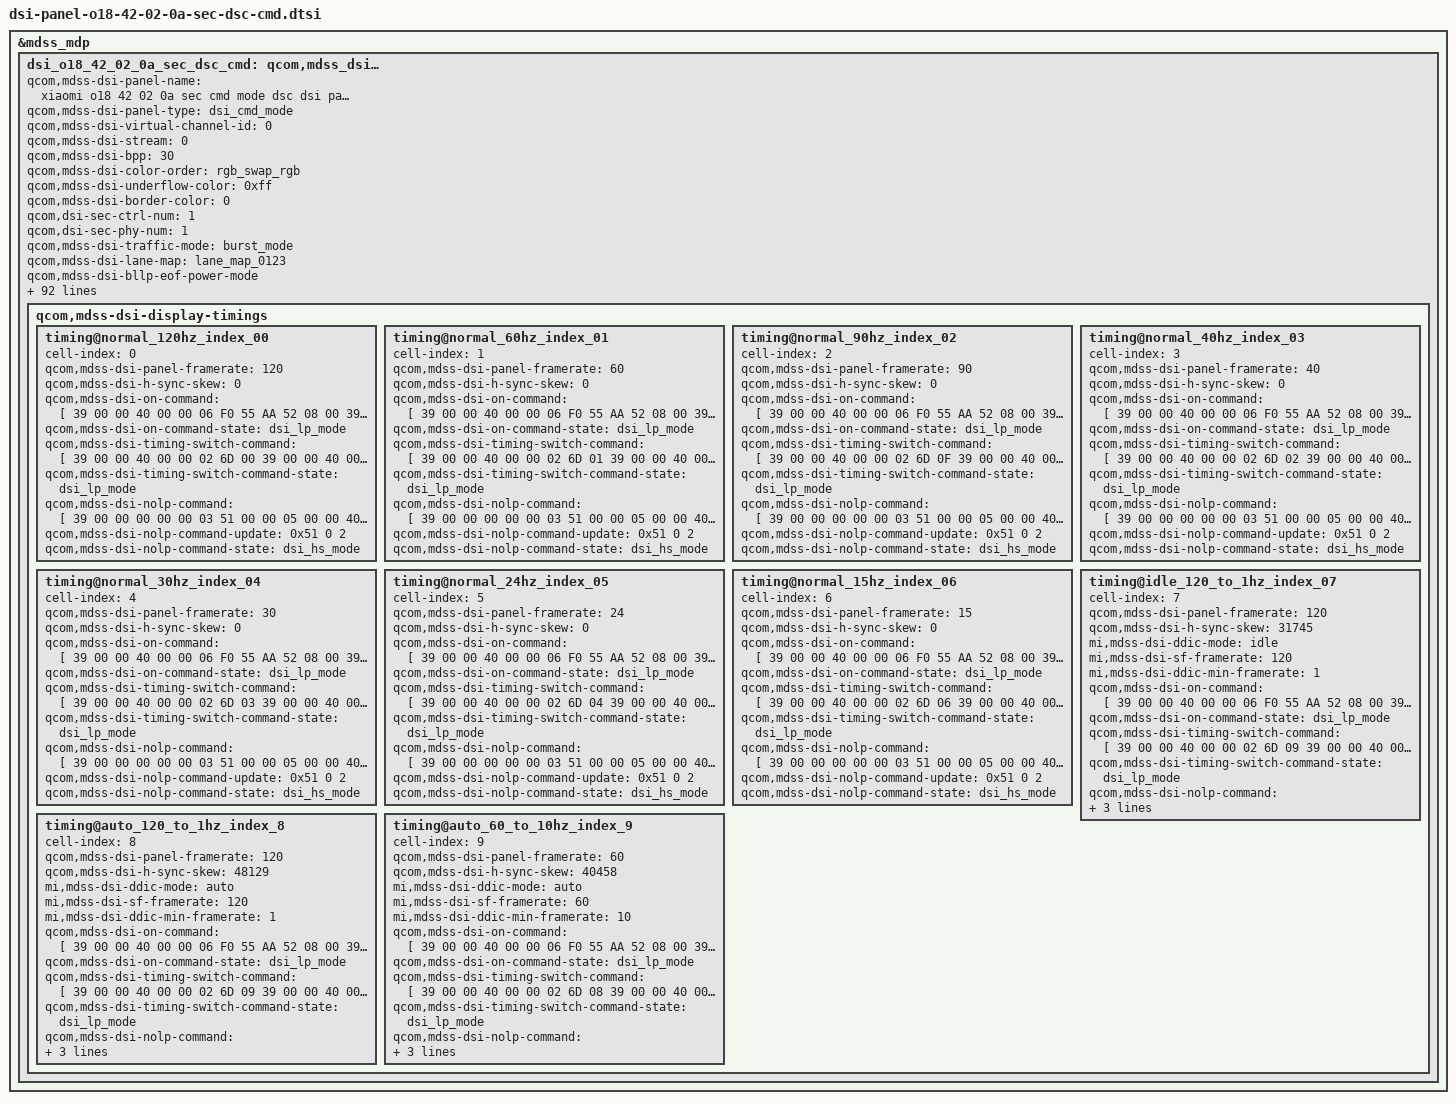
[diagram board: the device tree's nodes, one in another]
&mdss_mdp {
	dsi_o18_42_02_0a_sec_dsc_cmd: qcom,mdss_dsi_o18_42_02_0a_sec_dsc_cmd {
		qcom,mdss-dsi-panel-name = "xiaomi o18 42 02 0a sec cmd mode dsc dsi panel";
		qcom,mdss-dsi-panel-type = "dsi_cmd_mode";
		qcom,mdss-dsi-virtual-channel-id = <0>;
		qcom,mdss-dsi-stream = <0>;
		qcom,mdss-dsi-bpp = <30>;
		qcom,mdss-dsi-color-order = "rgb_swap_rgb";
		qcom,mdss-dsi-underflow-color = <0xff>;
		qcom,mdss-dsi-border-color = <0>;
		qcom,dsi-sec-ctrl-num = <1>;
		qcom,dsi-sec-phy-num = <1>;

		qcom,mdss-dsi-traffic-mode = "burst_mode";
		qcom,mdss-dsi-lane-map = "lane_map_0123";
		qcom,mdss-dsi-bllp-eof-power-mode;
		qcom,mdss-dsi-bllp-power-mode;
		qcom,mdss-dsi-lane-0-state;
		qcom,mdss-dsi-lane-1-state;
		qcom,mdss-dsi-lane-2-state;
		qcom,mdss-dsi-lane-3-state;
		qcom,mdss-dsi-dma-trigger = "trigger_sw";
		qcom,mdss-dsi-mdp-trigger = "none";
		qcom,mdss-dsi-reset-sequence = <0 1>, <1 10>;
		qcom,mdss-pan-physical-width-dimension = <656>;
		qcom,mdss-pan-physical-height-dimension = <1533>;
		qcom,mdss-dsi-te-pin-select = <1>;
		qcom,mdss-dsi-wr-mem-start = <0x2c>;
		qcom,mdss-dsi-wr-mem-continue = <0x3c>;
		qcom,mdss-dsi-te-dcs-command = <1>;
		qcom,mdss-dsi-te-check-enable;
		qcom,mdss-dsi-te-using-te-pin;
		qcom,mdss-dsi-tx-eot-append;
		qcom,mdss-dsi-lp11-init;

		qcom,mdss-dsi-bl-inverted-dbv;
		qcom,bl-update-flag = "delay_until_first_frame";

		qcom,mdss-dsi-panel-hdr-enabled;
		qcom,mdss-dsi-panel-hdr-color-primaries = <14500 15500 32000
			17000 15500 30000 8000 3000>;
		qcom,mdss-dsi-panel-peak-brightness = <17000000>;
		qcom,mdss-dsi-panel-blackness-level = <3230>;

		qcom,mdss-dsi-dma-schedule-line = <1>;
		qcom,mdss-dsi-dma-schedule-window = <50>;

		/* IRQF_ONESHOT | IRQF_TRIGGER_HIGH */
		/*mi,esd-err-irq-gpio = <&tlmm 137 0x2004>;*/
		//qcom,spr-pack-type = "pentile";

		mi,panel-id = <0x004F3138 0x5342020A>;

		mi,ddic-round-corner-enabled;
		qcom,mdss-disable-cesta-hw-sleep;

		mi,flat-need-sync-te;
		mi,flatmode-default-on-enabled;

		mi,flatmode-status-check-enabled;
		mi,mdss-dsi-panel-flatmode-status-command = [
			06 01 00 01 00 00 01 5F
		];
		mi,mdss-dsi-panel-flatmode-status-command-state = "dsi_hs_mode";
		mi,mdss-dsi-panel-flatmode-status-read-length = <2>;
		mi,mdss-dsi-panel-flatmode-on-status-value = <0x00>,<0x40>;

		mi,mdss-dsi-panel-wp-read-command = [06 01 00 01 00 00 01 DF];
		mi,mdss-dsi-panel-wp-read-command-state = "dsi_hs_mode";
		mi,mdss-dsi-panel-wp-read-pre-tx-command = [39 00 00 40 00 00 06 F0 55 AA 52 08 03];
		mi,mdss-dsi-panel-wp-read-pre-tx-command-state = "dsi_hs_mode";
		mi,mdss-dsi-panel-wp-read-length = <16>;

		mi,mdss-dsi-panel-cell-id-read-command = [06 01 00 01 00 00 01 B1];
		mi,mdss-dsi-panel-cell-id-read-pre-tx-command = [
			39 00 00 40 00 00 06 F0 55 AA 52 08 00
			15 00 00 00 00 00 02 EA 10
		];
		mi,mdss-dsi-panel-cell-id-read-after-tx-command = [
			39 00 00 40 00 00 06 F0 55 AA 52 08 00
			15 00 00 00 00 00 02 EA 00
		];
		mi,mdss-dsi-panel-cell-id-read-pre-tx-command-state = "dsi_hs_mode";
		mi,mdss-dsi-panel-cell-id-read-after-tx-command-state = "dsi_hs_mode";
		mi,mdss-dsi-panel-cell-id-read-command-state = "dsi_hs_mode";
		mi,mdss-dsi-panel-cell-id-read-length = <13>;
		/* esd-check reg_read */
		//qcom,esd-check-enabled;
		//qcom,esd-aod-check-enabled;
		//mi,mdss-dsi-panel-status-check-interval = <1000>;
		//qcom,mdss-dsi-panel-status-check-mode = "reg_read";
		//mi,mdss-dsi-panel-status-offset-command = [39 00 00 00 00 00 03 FF 5A 82
		//						  39 00 00 00 00 00 02 65 01];
		//qcom,mdss-dsi-panel-status-command = [06 01 00 00 00 00 01 F9];
		//mi,mdss-dsi-panel-status-after-command = [39 00 00 00 00 00 03 FF 5A 00];
		//qcom,mdss-dsi-panel-status-command-state = "dsi_lp_mode";
		//mi,mdss-dsi-panel-status-offset-command-state = "dsi_lp_mode";
		//mi,mdss-dsi-panel-status-after-command-state = "dsi_lp_mode";
		//qcom,mdss-dsi-panel-status-value = <0x08>;
		//qcom,mdss-dsi-panel-status-read-length = <1>;

		mi,panel-on-dimming-delay = <120>;
		mi,max-brightness-clone = <16383>;

		mi,mdss-dsi-fac-bl-max-level = <11467>;
		mi,mdss-fac-brightness-max-level = <11467>;
		mi,doze-hbm-dbv-level = <984>;
		mi,doze-lbm-dbv-level = <65>;

		qcom,mdss-dsi-display-timings {
			timing@normal_120hz_index_00 {
				#include "dsi-panel-o18-42-02-0a-sec-dsc-cmd-common.dtsi"
				cell-index = <0>;
				qcom,mdss-dsi-panel-framerate = <120>;
				qcom,mdss-dsi-h-sync-skew = <0>;
				qcom,mdss-dsi-on-command = [
					39 00 00 40 00 00 06 F0 55 AA 52 08 00
					39 00 00 40 00 00 02 6F 78
					39 00 00 40 00 00 18 B0 11 00 2A 00 C2 01 DA 03 7C 05 B1 08 80 0B EE 0F FF 05 55 05 56 05 55
					39 00 00 40 00 00 02 6F 6F
					39 00 00 40 00 00 07 B0 02 1C 04 38 02 1C
					39 00 00 40 00 00 06 F0 55 AA 52 08 08
					39 00 00 40 00 00 17 C1 8D FF DD FF FF DD FF FF DD FF FF EE FF FF EE FF FF FE FF FF 0D FF
					39 00 00 40 00 00 02 6F 20
					39 00 00 40 00 00 04 C1 4F 00 FF
					39 00 00 40 00 00 02 6F 23
					39 00 00 40 00 00 15 C1 0D FF DD FF FF DD FF FF DD FF FF EE FF FF EE FF FF CE FF 51
					39 00 00 40 00 00 06 F0 55 AA 52 08 00
					39 00 00 40 00 00 02 C7 33
					39 00 00 40 00 00 02 6F 31
					39 00 00 40 00 00 03 C0 02 00
					39 00 00 40 00 00 06 F0 55 AA 52 08 04
					39 00 00 40 00 00 02 C0 20
					39 00 00 40 00 00 06 F0 55 AA 52 08 01
					39 00 00 40 00 00 03 B0 17 17
					39 00 00 40 00 00 06 B2 00 00 FF 03 20
					39 00 00 40 00 00 05 FF AA 55 A5 80
					39 00 00 40 00 00 02 6F 0A
					39 00 00 40 00 00 06 F6 70 70 70 70 70
					39 00 00 40 00 00 05 FF AA 55 A5 81
					39 00 00 40 00 00 02 6F 0C
					39 00 00 40 00 00 02 FD 08
					39 00 00 40 00 00 05 FF AA 55 A5 81
					39 00 00 40 00 00 02 6F 10
					39 00 00 40 00 00 02 FB 40
					39 00 00 40 00 00 05 FF AA 55 A5 81
					39 00 00 40 00 00 02 6F 13
					39 00 00 40 00 00 02 F9 00
					39 00 00 40 00 00 02 17 30
					39 00 00 40 00 00 05 2A 00 00 04 37
					39 00 00 40 00 00 05 2B 00 00 09 D7
					39 00 00 40 00 00 02 90 03
					39 00 00 40 00 00 02 6F 01
					39 00 00 40 00 00 02 90 43
					39 00 00 40 00 00 13 91 AB A8 00 14 C2 00 02 0E 01 E8 00 07 05 0E 05 16 10 F0
					39 00 00 40 00 00 02 6F 06
					39 00 00 40 00 00 02 6D 04
					39 00 00 40 00 00 02 2F 00
					39 00 00 40 00 00 03 5F 00 40
					39 00 00 40 00 00 02 35 00
					39 00 00 40 00 00 02 53 20
					39 00 00 40 00 00 02 26 00
					39 00 00 40 00 00 02 5A 00
					39 00 00 40 00 00 02 2F 30
					/* normal 120hz */
					39 00 00 40 00 00 02 6D 00
					39 00 00 40 00 00 02 6F 04
					39 00 00 40 00 00 02 35 00
					39 00 00 40 00 00 06 F0 55 AA 52 08 00
					39 00 00 40 00 00 02 6F DE
					39 00 00 40 00 00 02 BA 04
					39 00 00 00 00 00 04 8C 02 00 11
					05 00 00 00 78 00 01 11
					05 00 00 00 00 00 01 29
				];
				qcom,mdss-dsi-on-command-state = "dsi_lp_mode";

				qcom,mdss-dsi-timing-switch-command = [
					39 00 00 40 00 00 02 6D 00
					39 00 00 40 00 00 02 6F 04
					39 00 00 40 00 00 02 35 00
					39 00 00 40 00 00 06 F0 55 AA 52 08 00
					39 00 00 40 00 00 02 6F DE
					39 00 00 40 00 00 02 BA 04
					39 00 00 00 00 00 04 8C 02 00 11
				];
				qcom,mdss-dsi-timing-switch-command-state = "dsi_lp_mode";

				qcom,mdss-dsi-nolp-command = [
					39 00 00 00 00 00 03 51 00 00
					/* AOD OFF */
					05 00 00 40 00 00 01 38
				];
				qcom,mdss-dsi-nolp-command-update = <0x51 0 2>;
				qcom,mdss-dsi-nolp-command-state = "dsi_hs_mode";

			};
			timing@normal_60hz_index_01 {
				#include "dsi-panel-o18-42-02-0a-sec-dsc-cmd-common.dtsi"
				cell-index = <1>;
				qcom,mdss-dsi-panel-framerate = <60>;
				qcom,mdss-dsi-h-sync-skew = <0>;

				qcom,mdss-dsi-on-command = [
					39 00 00 40 00 00 06 F0 55 AA 52 08 00
					39 00 00 40 00 00 02 6F 78
					39 00 00 40 00 00 18 B0 11 00 2A 00 C2 01 DA 03 7C 05 B1 08 80 0B EE 0F FF 05 55 05 56 05 55
					39 00 00 40 00 00 02 6F 6F
					39 00 00 40 00 00 07 B0 02 1C 04 38 02 1C
					39 00 00 40 00 00 06 F0 55 AA 52 08 08
					39 00 00 40 00 00 17 C1 8D FF DD FF FF DD FF FF DD FF FF EE FF FF EE FF FF FE FF FF 0D FF
					39 00 00 40 00 00 02 6F 20
					39 00 00 40 00 00 04 C1 4F 00 FF
					39 00 00 40 00 00 02 6F 23
					39 00 00 40 00 00 15 C1 0D FF DD FF FF DD FF FF DD FF FF EE FF FF EE FF FF CE FF 51
					39 00 00 40 00 00 06 F0 55 AA 52 08 00
					39 00 00 40 00 00 02 C7 33
					39 00 00 40 00 00 02 6F 31
					39 00 00 40 00 00 03 C0 02 00
					39 00 00 40 00 00 06 F0 55 AA 52 08 04
					39 00 00 40 00 00 02 C0 20
					39 00 00 40 00 00 06 F0 55 AA 52 08 01
					39 00 00 40 00 00 03 B0 17 17
					39 00 00 40 00 00 06 B2 00 00 FF 03 20
					39 00 00 40 00 00 05 FF AA 55 A5 80
					39 00 00 40 00 00 02 6F 0A
					39 00 00 40 00 00 06 F6 70 70 70 70 70
					39 00 00 40 00 00 05 FF AA 55 A5 81
					39 00 00 40 00 00 02 6F 0C
					39 00 00 40 00 00 02 FD 08
					39 00 00 40 00 00 05 FF AA 55 A5 81
					39 00 00 40 00 00 02 6F 10
					39 00 00 40 00 00 02 FB 40
					39 00 00 40 00 00 05 FF AA 55 A5 81
					39 00 00 40 00 00 02 6F 13
					39 00 00 40 00 00 02 F9 00
					39 00 00 40 00 00 02 17 30
					39 00 00 40 00 00 05 2A 00 00 04 37
					39 00 00 40 00 00 05 2B 00 00 09 D7
					39 00 00 40 00 00 02 90 03
					39 00 00 40 00 00 02 6F 01
					39 00 00 40 00 00 02 90 43
					39 00 00 40 00 00 13 91 AB A8 00 14 C2 00 02 0E 01 E8 00 07 05 0E 05 16 10 F0
					39 00 00 40 00 00 02 6F 06
					39 00 00 40 00 00 02 6D 04
					39 00 00 40 00 00 02 2F 00
					39 00 00 40 00 00 03 5F 00 40
					39 00 00 40 00 00 02 35 00
					39 00 00 40 00 00 02 53 20
					39 00 00 40 00 00 02 26 00
					39 00 00 40 00 00 02 5A 00
					39 00 00 40 00 00 02 2F 30
					/* normal 60hz */
					39 00 00 40 00 00 02 6D 01
					39 00 00 40 00 00 02 6F 04
					39 00 00 40 00 00 02 35 01
					39 00 00 40 00 00 06 F0 55 AA 52 08 00
					39 00 00 40 00 00 02 6F DE
					39 00 00 40 00 00 02 BA 04
					39 00 00 00 00 00 04 8C 02 00 11
					05 00 00 00 78 00 01 11
					05 00 00 00 00 00 01 29
				];
				qcom,mdss-dsi-on-command-state = "dsi_lp_mode";

				qcom,mdss-dsi-timing-switch-command = [
					39 00 00 40 00 00 02 6D 01
					39 00 00 40 00 00 02 6F 04
					39 00 00 40 00 00 02 35 01
					39 00 00 40 00 00 06 F0 55 AA 52 08 00
					39 00 00 40 00 00 02 6F DE
					39 00 00 40 00 00 02 BA 04
					39 00 00 00 00 00 04 8C 02 00 11
				];
				qcom,mdss-dsi-timing-switch-command-state = "dsi_lp_mode";

				qcom,mdss-dsi-nolp-command = [
					39 00 00 00 00 00 03 51 00 00
					/* AOD OFF */
					05 00 00 40 00 00 01 38
					39 00 00 40 00 00 02 5A 00
					39 00 00 40 00 00 02 6F 04
					39 00 00 00 00 00 02 35 01
				];
				qcom,mdss-dsi-nolp-command-update = <0x51 0 2>;
				qcom,mdss-dsi-nolp-command-state = "dsi_hs_mode";
			};

			timing@normal_90hz_index_02 {
				#include "dsi-panel-o18-42-02-0a-sec-dsc-cmd-common.dtsi"
				cell-index = <2>;
				qcom,mdss-dsi-panel-framerate = <90>;
				qcom,mdss-dsi-h-sync-skew = <0>;

				qcom,mdss-dsi-on-command = [
					39 00 00 40 00 00 06 F0 55 AA 52 08 00
					39 00 00 40 00 00 02 6F 78
					39 00 00 40 00 00 18 B0 11 00 2A 00 C2 01 DA 03 7C 05 B1 08 80 0B EE 0F FF 05 55 05 56 05 55
					39 00 00 40 00 00 02 6F 6F
					39 00 00 40 00 00 07 B0 02 1C 04 38 02 1C
					39 00 00 40 00 00 06 F0 55 AA 52 08 08
					39 00 00 40 00 00 17 C1 8D FF DD FF FF DD FF FF DD FF FF EE FF FF EE FF FF FE FF FF 0D FF
					39 00 00 40 00 00 02 6F 20
					39 00 00 40 00 00 04 C1 4F 00 FF
					39 00 00 40 00 00 02 6F 23
					39 00 00 40 00 00 15 C1 0D FF DD FF FF DD FF FF DD FF FF EE FF FF EE FF FF CE FF 51
					39 00 00 40 00 00 06 F0 55 AA 52 08 00
					39 00 00 40 00 00 02 C7 33
					39 00 00 40 00 00 02 6F 31
					39 00 00 40 00 00 03 C0 02 00
					39 00 00 40 00 00 06 F0 55 AA 52 08 04
					39 00 00 40 00 00 02 C0 20
					39 00 00 40 00 00 06 F0 55 AA 52 08 01
					39 00 00 40 00 00 03 B0 17 17
					39 00 00 40 00 00 06 B2 00 00 FF 03 20
					39 00 00 40 00 00 05 FF AA 55 A5 80
					39 00 00 40 00 00 02 6F 0A
					39 00 00 40 00 00 06 F6 70 70 70 70 70
					39 00 00 40 00 00 05 FF AA 55 A5 81
					39 00 00 40 00 00 02 6F 0C
					39 00 00 40 00 00 02 FD 08
					39 00 00 40 00 00 05 FF AA 55 A5 81
					39 00 00 40 00 00 02 6F 10
					39 00 00 40 00 00 02 FB 40
					39 00 00 40 00 00 05 FF AA 55 A5 81
					39 00 00 40 00 00 02 6F 13
					39 00 00 40 00 00 02 F9 00
					39 00 00 40 00 00 02 17 30
					39 00 00 40 00 00 05 2A 00 00 04 37
					39 00 00 40 00 00 05 2B 00 00 09 D7
					39 00 00 40 00 00 02 90 03
					39 00 00 40 00 00 02 6F 01
					39 00 00 40 00 00 02 90 43
					39 00 00 40 00 00 13 91 AB A8 00 14 C2 00 02 0E 01 E8 00 07 05 0E 05 16 10 F0
					39 00 00 40 00 00 02 6F 06
					39 00 00 40 00 00 02 6D 04
					39 00 00 40 00 00 02 2F 00
					39 00 00 40 00 00 03 5F 00 40
					39 00 00 40 00 00 02 35 00
					39 00 00 40 00 00 02 53 20
					39 00 00 40 00 00 02 26 00
					39 00 00 40 00 00 02 5A 00
					39 00 00 40 00 00 02 2F 30
					/* normal 90hz */
					39 00 00 40 00 00 02 6D 0F
					39 00 00 40 00 00 02 6F 04
					39 00 00 40 00 00 02 35 00
					39 00 00 40 00 00 06 F0 55 AA 52 08 00
					39 00 00 40 00 00 02 6F DE
					39 00 00 40 00 00 02 BA 00
					39 00 00 00 00 00 04 8C 02 00 11
					05 00 00 00 78 00 01 11
					05 00 00 00 00 00 01 29
				];
				qcom,mdss-dsi-on-command-state = "dsi_lp_mode";

				qcom,mdss-dsi-timing-switch-command = [
					39 00 00 40 00 00 02 6D 0F
					39 00 00 40 00 00 02 6F 04
					39 00 00 40 00 00 02 35 00
					39 00 00 40 00 00 06 F0 55 AA 52 08 00
					39 00 00 40 00 00 02 6F DE
					39 00 00 40 00 00 02 BA 00
					39 00 00 00 00 00 04 8C 02 00 11
				];
				qcom,mdss-dsi-timing-switch-command-state = "dsi_lp_mode";

				qcom,mdss-dsi-nolp-command = [
					39 00 00 00 00 00 03 51 00 00
					/* AOD OFF */
					05 00 00 40 00 00 01 38
					39 00 00 40 00 00 02 5A 00
					39 00 00 40 00 00 02 6F 04
					39 00 00 00 00 00 02 35 00
				];
				qcom,mdss-dsi-nolp-command-update = <0x51 0 2>;
				qcom,mdss-dsi-nolp-command-state = "dsi_hs_mode";
			};

			timing@normal_40hz_index_03 {
				#include "dsi-panel-o18-42-02-0a-sec-dsc-cmd-common.dtsi"
				cell-index = <3>;
				qcom,mdss-dsi-panel-framerate = <40>;
				qcom,mdss-dsi-h-sync-skew = <0>;

				qcom,mdss-dsi-on-command = [
					39 00 00 40 00 00 06 F0 55 AA 52 08 00
					39 00 00 40 00 00 02 6F 78
					39 00 00 40 00 00 18 B0 11 00 2A 00 C2 01 DA 03 7C 05 B1 08 80 0B EE 0F FF 05 55 05 56 05 55
					39 00 00 40 00 00 02 6F 6F
					39 00 00 40 00 00 07 B0 02 1C 04 38 02 1C
					39 00 00 40 00 00 06 F0 55 AA 52 08 08
					39 00 00 40 00 00 17 C1 8D FF DD FF FF DD FF FF DD FF FF EE FF FF EE FF FF FE FF FF 0D FF
					39 00 00 40 00 00 02 6F 20
					39 00 00 40 00 00 04 C1 4F 00 FF
					39 00 00 40 00 00 02 6F 23
					39 00 00 40 00 00 15 C1 0D FF DD FF FF DD FF FF DD FF FF EE FF FF EE FF FF CE FF 51
					39 00 00 40 00 00 06 F0 55 AA 52 08 00
					39 00 00 40 00 00 02 C7 33
					39 00 00 40 00 00 02 6F 31
					39 00 00 40 00 00 03 C0 02 00
					39 00 00 40 00 00 06 F0 55 AA 52 08 04
					39 00 00 40 00 00 02 C0 20
					39 00 00 40 00 00 06 F0 55 AA 52 08 01
					39 00 00 40 00 00 03 B0 17 17
					39 00 00 40 00 00 06 B2 00 00 FF 03 20
					39 00 00 40 00 00 05 FF AA 55 A5 80
					39 00 00 40 00 00 02 6F 0A
					39 00 00 40 00 00 06 F6 70 70 70 70 70
					39 00 00 40 00 00 05 FF AA 55 A5 81
					39 00 00 40 00 00 02 6F 0C
					39 00 00 40 00 00 02 FD 08
					39 00 00 40 00 00 05 FF AA 55 A5 81
					39 00 00 40 00 00 02 6F 10
					39 00 00 40 00 00 02 FB 40
					39 00 00 40 00 00 05 FF AA 55 A5 81
					39 00 00 40 00 00 02 6F 13
					39 00 00 40 00 00 02 F9 00
					39 00 00 40 00 00 02 17 30
					39 00 00 40 00 00 05 2A 00 00 04 37
					39 00 00 40 00 00 05 2B 00 00 09 D7
					39 00 00 40 00 00 02 90 03
					39 00 00 40 00 00 02 6F 01
					39 00 00 40 00 00 02 90 43
					39 00 00 40 00 00 13 91 AB A8 00 14 C2 00 02 0E 01 E8 00 07 05 0E 05 16 10 F0
					39 00 00 40 00 00 02 6F 06
					39 00 00 40 00 00 02 6D 04
					39 00 00 40 00 00 02 2F 00
					39 00 00 40 00 00 03 5F 00 40
					39 00 00 40 00 00 02 35 00
					39 00 00 40 00 00 02 53 20
					39 00 00 40 00 00 02 26 00
					39 00 00 40 00 00 02 5A 00
					39 00 00 40 00 00 02 2F 30
					/* normal 40hz */
					39 00 00 40 00 00 02 6D 02
					39 00 00 40 00 00 02 6F 04
					39 00 00 40 00 00 02 35 02
					39 00 00 40 00 00 06 F0 55 AA 52 08 00
					39 00 00 40 00 00 02 6F DE
					39 00 00 40 00 00 02 BA 04
					39 00 00 00 00 00 04 8C 02 00 11
					05 00 00 00 78 00 01 11
					05 00 00 00 00 00 01 29
				];
				qcom,mdss-dsi-on-command-state = "dsi_lp_mode";

				qcom,mdss-dsi-timing-switch-command = [
					39 00 00 40 00 00 02 6D 02
					39 00 00 40 00 00 02 6F 04
					39 00 00 40 00 00 02 35 02
					39 00 00 40 00 00 06 F0 55 AA 52 08 00
					39 00 00 40 00 00 02 6F DE
					39 00 00 40 00 00 02 BA 04
					39 00 00 00 00 00 04 8C 02 00 11
				];
				qcom,mdss-dsi-timing-switch-command-state = "dsi_lp_mode";

				qcom,mdss-dsi-nolp-command = [
					39 00 00 00 00 00 03 51 00 00
					/* AOD OFF */
					05 00 00 40 00 00 01 38
					39 00 00 40 00 00 02 5A 00
					39 00 00 40 00 00 02 6F 04
					39 00 00 00 00 00 02 35 02
				];
				qcom,mdss-dsi-nolp-command-update = <0x51 0 2>;
				qcom,mdss-dsi-nolp-command-state = "dsi_hs_mode";
			};

			timing@normal_30hz_index_04 {
				#include "dsi-panel-o18-42-02-0a-sec-dsc-cmd-common.dtsi"
				cell-index = <4>;
				qcom,mdss-dsi-panel-framerate = <30>;
				qcom,mdss-dsi-h-sync-skew = <0>;

				qcom,mdss-dsi-on-command = [
					39 00 00 40 00 00 06 F0 55 AA 52 08 00
					39 00 00 40 00 00 02 6F 78
					39 00 00 40 00 00 18 B0 11 00 2A 00 C2 01 DA 03 7C 05 B1 08 80 0B EE 0F FF 05 55 05 56 05 55
					39 00 00 40 00 00 02 6F 6F
					39 00 00 40 00 00 07 B0 02 1C 04 38 02 1C
					39 00 00 40 00 00 06 F0 55 AA 52 08 08
					39 00 00 40 00 00 17 C1 8D FF DD FF FF DD FF FF DD FF FF EE FF FF EE FF FF FE FF FF 0D FF
					39 00 00 40 00 00 02 6F 20
					39 00 00 40 00 00 04 C1 4F 00 FF
					39 00 00 40 00 00 02 6F 23
					39 00 00 40 00 00 15 C1 0D FF DD FF FF DD FF FF DD FF FF EE FF FF EE FF FF CE FF 51
					39 00 00 40 00 00 06 F0 55 AA 52 08 00
					39 00 00 40 00 00 02 C7 33
					39 00 00 40 00 00 02 6F 31
					39 00 00 40 00 00 03 C0 02 00
					39 00 00 40 00 00 06 F0 55 AA 52 08 04
					39 00 00 40 00 00 02 C0 20
					39 00 00 40 00 00 06 F0 55 AA 52 08 01
					39 00 00 40 00 00 03 B0 17 17
					39 00 00 40 00 00 06 B2 00 00 FF 03 20
					39 00 00 40 00 00 05 FF AA 55 A5 80
					39 00 00 40 00 00 02 6F 0A
					39 00 00 40 00 00 06 F6 70 70 70 70 70
					39 00 00 40 00 00 05 FF AA 55 A5 81
					39 00 00 40 00 00 02 6F 0C
					39 00 00 40 00 00 02 FD 08
					39 00 00 40 00 00 05 FF AA 55 A5 81
					39 00 00 40 00 00 02 6F 10
					39 00 00 40 00 00 02 FB 40
					39 00 00 40 00 00 05 FF AA 55 A5 81
					39 00 00 40 00 00 02 6F 13
					39 00 00 40 00 00 02 F9 00
					39 00 00 40 00 00 02 17 30
					39 00 00 40 00 00 05 2A 00 00 04 37
					39 00 00 40 00 00 05 2B 00 00 09 D7
					39 00 00 40 00 00 02 90 03
					39 00 00 40 00 00 02 6F 01
					39 00 00 40 00 00 02 90 43
					39 00 00 40 00 00 13 91 AB A8 00 14 C2 00 02 0E 01 E8 00 07 05 0E 05 16 10 F0
					39 00 00 40 00 00 02 6F 06
					39 00 00 40 00 00 02 6D 04
					39 00 00 40 00 00 02 2F 00
					39 00 00 40 00 00 03 5F 00 40
					39 00 00 40 00 00 02 35 00
					39 00 00 40 00 00 02 53 20
					39 00 00 40 00 00 02 26 00
					39 00 00 40 00 00 02 5A 00
					39 00 00 40 00 00 02 2F 30
					/* normal 30hz */
					39 00 00 40 00 00 02 6D 03
					39 00 00 40 00 00 02 6F 04
					39 00 00 40 00 00 02 35 03
					39 00 00 40 00 00 06 F0 55 AA 52 08 00
					39 00 00 40 00 00 02 6F DE
					39 00 00 40 00 00 02 BA 04
					39 00 00 00 00 00 04 8C 02 00 11
					05 00 00 00 78 00 01 11
					05 00 00 00 00 00 01 29
				];
				qcom,mdss-dsi-on-command-state = "dsi_lp_mode";

				qcom,mdss-dsi-timing-switch-command = [
					39 00 00 40 00 00 02 6D 03
					39 00 00 40 00 00 02 6F 04
					39 00 00 40 00 00 02 35 03
					39 00 00 40 00 00 06 F0 55 AA 52 08 00
					39 00 00 40 00 00 02 6F DE
					39 00 00 40 00 00 02 BA 04
					39 00 00 00 00 00 04 8C 02 00 11
				];
				qcom,mdss-dsi-timing-switch-command-state = "dsi_lp_mode";

				qcom,mdss-dsi-nolp-command = [
					39 00 00 00 00 00 03 51 00 00
					/* AOD OFF */
					05 00 00 40 00 00 01 38
					39 00 00 40 00 00 02 5A 00
					39 00 00 40 00 00 02 6F 04
					39 00 00 00 00 00 02 35 03
				];
				qcom,mdss-dsi-nolp-command-update = <0x51 0 2>;
				qcom,mdss-dsi-nolp-command-state = "dsi_hs_mode";
			};

			timing@normal_24hz_index_05 {
				#include "dsi-panel-o18-42-02-0a-sec-dsc-cmd-common.dtsi"
				cell-index = <5>;
				qcom,mdss-dsi-panel-framerate = <24>;
				qcom,mdss-dsi-h-sync-skew = <0>;

				qcom,mdss-dsi-on-command = [
					39 00 00 40 00 00 06 F0 55 AA 52 08 00
					39 00 00 40 00 00 02 6F 78
					39 00 00 40 00 00 18 B0 11 00 2A 00 C2 01 DA 03 7C 05 B1 08 80 0B EE 0F FF 05 55 05 56 05 55
					39 00 00 40 00 00 02 6F 6F
					39 00 00 40 00 00 07 B0 02 1C 04 38 02 1C
					39 00 00 40 00 00 06 F0 55 AA 52 08 08
					39 00 00 40 00 00 17 C1 8D FF DD FF FF DD FF FF DD FF FF EE FF FF EE FF FF FE FF FF 0D FF
					39 00 00 40 00 00 02 6F 20
					39 00 00 40 00 00 04 C1 4F 00 FF
					39 00 00 40 00 00 02 6F 23
					39 00 00 40 00 00 15 C1 0D FF DD FF FF DD FF FF DD FF FF EE FF FF EE FF FF CE FF 51
					39 00 00 40 00 00 06 F0 55 AA 52 08 00
					39 00 00 40 00 00 02 C7 33
					39 00 00 40 00 00 02 6F 31
					39 00 00 40 00 00 03 C0 02 00
					39 00 00 40 00 00 06 F0 55 AA 52 08 04
					39 00 00 40 00 00 02 C0 20
					39 00 00 40 00 00 06 F0 55 AA 52 08 01
					39 00 00 40 00 00 03 B0 17 17
					39 00 00 40 00 00 06 B2 00 00 FF 03 20
					39 00 00 40 00 00 05 FF AA 55 A5 80
					39 00 00 40 00 00 02 6F 0A
					39 00 00 40 00 00 06 F6 70 70 70 70 70
					39 00 00 40 00 00 05 FF AA 55 A5 81
					39 00 00 40 00 00 02 6F 0C
					39 00 00 40 00 00 02 FD 08
					39 00 00 40 00 00 05 FF AA 55 A5 81
					39 00 00 40 00 00 02 6F 10
					39 00 00 40 00 00 02 FB 40
					39 00 00 40 00 00 05 FF AA 55 A5 81
					39 00 00 40 00 00 02 6F 13
					39 00 00 40 00 00 02 F9 00
					39 00 00 40 00 00 02 17 30
					39 00 00 40 00 00 05 2A 00 00 04 37
					39 00 00 40 00 00 05 2B 00 00 09 D7
					39 00 00 40 00 00 02 90 03
					39 00 00 40 00 00 02 6F 01
					39 00 00 40 00 00 02 90 43
					39 00 00 40 00 00 13 91 AB A8 00 14 C2 00 02 0E 01 E8 00 07 05 0E 05 16 10 F0
					39 00 00 40 00 00 02 6F 06
					39 00 00 40 00 00 02 6D 04
					39 00 00 40 00 00 02 2F 00
					39 00 00 40 00 00 03 5F 00 40
					39 00 00 40 00 00 02 35 00
					39 00 00 40 00 00 02 53 20
					39 00 00 40 00 00 02 26 00
					39 00 00 40 00 00 02 5A 00
					39 00 00 40 00 00 02 2F 30
					/* normal 24hz */
					39 00 00 40 00 00 02 6D 04
					39 00 00 40 00 00 02 6F 04
					39 00 00 40 00 00 02 35 04
					39 00 00 40 00 00 06 F0 55 AA 52 08 00
					39 00 00 40 00 00 02 6F DE
					39 00 00 40 00 00 02 BA 04
					39 00 00 00 00 00 04 8C 02 00 11
					05 00 00 00 78 00 01 11
					05 00 00 00 00 00 01 29
				];
				qcom,mdss-dsi-on-command-state = "dsi_lp_mode";

				qcom,mdss-dsi-timing-switch-command = [
					39 00 00 40 00 00 02 6D 04
					39 00 00 40 00 00 02 6F 04
					39 00 00 40 00 00 02 35 04
					39 00 00 40 00 00 06 F0 55 AA 52 08 00
					39 00 00 40 00 00 02 6F DE
					39 00 00 40 00 00 02 BA 04
					39 00 00 00 00 00 04 8C 02 00 11
				];
				qcom,mdss-dsi-timing-switch-command-state = "dsi_lp_mode";

				qcom,mdss-dsi-nolp-command = [
					39 00 00 00 00 00 03 51 00 00
					/* AOD OFF */
					05 00 00 40 00 00 01 38
					39 00 00 40 00 00 02 5A 00
					39 00 00 40 00 00 02 6F 04
					39 00 00 00 00 00 02 35 04
				];
				qcom,mdss-dsi-nolp-command-update = <0x51 0 2>;
				qcom,mdss-dsi-nolp-command-state = "dsi_hs_mode";
			};

			timing@normal_15hz_index_06 {
				#include "dsi-panel-o18-42-02-0a-sec-dsc-cmd-common.dtsi"
				cell-index = <6>;
				qcom,mdss-dsi-panel-framerate = <15>;
				qcom,mdss-dsi-h-sync-skew = <0>;

				qcom,mdss-dsi-on-command = [
					39 00 00 40 00 00 06 F0 55 AA 52 08 00
					39 00 00 40 00 00 02 6F 78
					39 00 00 40 00 00 18 B0 11 00 2A 00 C2 01 DA 03 7C 05 B1 08 80 0B EE 0F FF 05 55 05 56 05 55
					39 00 00 40 00 00 02 6F 6F
					39 00 00 40 00 00 07 B0 02 1C 04 38 02 1C
					39 00 00 40 00 00 06 F0 55 AA 52 08 08
					39 00 00 40 00 00 17 C1 8D FF DD FF FF DD FF FF DD FF FF EE FF FF EE FF FF FE FF FF 0D FF
					39 00 00 40 00 00 02 6F 20
					39 00 00 40 00 00 04 C1 4F 00 FF
					39 00 00 40 00 00 02 6F 23
					39 00 00 40 00 00 15 C1 0D FF DD FF FF DD FF FF DD FF FF EE FF FF EE FF FF CE FF 51
					39 00 00 40 00 00 06 F0 55 AA 52 08 00
					39 00 00 40 00 00 02 C7 33
					39 00 00 40 00 00 02 6F 31
					39 00 00 40 00 00 03 C0 02 00
					39 00 00 40 00 00 06 F0 55 AA 52 08 04
					39 00 00 40 00 00 02 C0 20
					39 00 00 40 00 00 06 F0 55 AA 52 08 01
					39 00 00 40 00 00 03 B0 17 17
					39 00 00 40 00 00 06 B2 00 00 FF 03 20
					39 00 00 40 00 00 05 FF AA 55 A5 80
					39 00 00 40 00 00 02 6F 0A
					39 00 00 40 00 00 06 F6 70 70 70 70 70
					39 00 00 40 00 00 05 FF AA 55 A5 81
					39 00 00 40 00 00 02 6F 0C
					39 00 00 40 00 00 02 FD 08
					39 00 00 40 00 00 05 FF AA 55 A5 81
					39 00 00 40 00 00 02 6F 10
					39 00 00 40 00 00 02 FB 40
					39 00 00 40 00 00 05 FF AA 55 A5 81
					39 00 00 40 00 00 02 6F 13
					39 00 00 40 00 00 02 F9 00
					39 00 00 40 00 00 02 17 30
					39 00 00 40 00 00 05 2A 00 00 04 37
					39 00 00 40 00 00 05 2B 00 00 09 D7
					39 00 00 40 00 00 02 90 03
					39 00 00 40 00 00 02 6F 01
					39 00 00 40 00 00 02 90 43
					39 00 00 40 00 00 13 91 AB A8 00 14 C2 00 02 0E 01 E8 00 07 05 0E 05 16 10 F0
					39 00 00 40 00 00 02 6F 06
					39 00 00 40 00 00 02 6D 04
					39 00 00 40 00 00 02 2F 00
					39 00 00 40 00 00 03 5F 00 40
					39 00 00 40 00 00 02 35 00
					39 00 00 40 00 00 02 53 20
					39 00 00 40 00 00 02 26 00
					39 00 00 40 00 00 02 5A 00
					39 00 00 40 00 00 02 2F 30
					/* normal 24hz */
					39 00 00 40 00 00 02 6D 06
					39 00 00 40 00 00 02 6F 04
					39 00 00 40 00 00 02 35 07
					39 00 00 40 00 00 06 F0 55 AA 52 08 00
					39 00 00 40 00 00 02 6F DE
					39 00 00 40 00 00 02 BA 04
					39 00 00 00 00 00 04 8C 02 00 11
					05 00 00 00 78 00 01 11
					05 00 00 00 00 00 01 29
				];
				qcom,mdss-dsi-on-command-state = "dsi_lp_mode";

				qcom,mdss-dsi-timing-switch-command = [
					39 00 00 40 00 00 02 6D 06
					39 00 00 40 00 00 02 6F 04
					39 00 00 40 00 00 02 35 07
					39 00 00 40 00 00 06 F0 55 AA 52 08 00
					39 00 00 40 00 00 02 6F DE
					39 00 00 40 00 00 02 BA 04
					39 00 00 00 00 00 04 8C 02 00 11
				];
				qcom,mdss-dsi-timing-switch-command-state = "dsi_lp_mode";

				qcom,mdss-dsi-nolp-command = [
					39 00 00 00 00 00 03 51 00 00
					/* AOD OFF */
					05 00 00 40 00 00 01 38
					39 00 00 40 00 00 02 5A 00
					39 00 00 40 00 00 02 6F 04
					39 00 00 00 00 00 02 35 07
				];
				qcom,mdss-dsi-nolp-command-update = <0x51 0 2>;
				qcom,mdss-dsi-nolp-command-state = "dsi_hs_mode";
			};
			timing@idle_120_to_1hz_index_07 {
				#include "dsi-panel-o18-42-02-0a-sec-dsc-cmd-common.dtsi"
				cell-index = <7>;
				qcom,mdss-dsi-panel-framerate = <120>;
				/* ---------------------------- */
				/* | 15 - 14 | 13 - 7 | 6 - 0 | */
				/* ---------------------------- */
				/* |   mode  | sf fps | min fps| */
				/* ---------------------------- -*/
				/* mode: 1 idle, 2 auto, 3 qsync */
				/*   1 << 14 | 120 << 7 | 1     */
				qcom,mdss-dsi-h-sync-skew = <31745>;
				/* mode: 0 normal, 1 idle, 2 auto, 3 qsync, 4 diff, 5 test */
				mi,mdss-dsi-ddic-mode = "idle";
				mi,mdss-dsi-sf-framerate = <120>;
				mi,mdss-dsi-ddic-min-framerate = <1>;

				qcom,mdss-dsi-on-command = [
					39 00 00 40 00 00 06 F0 55 AA 52 08 00
					39 00 00 40 00 00 02 6F 78
					39 00 00 40 00 00 18 B0 11 00 2A 00 C2 01 DA 03 7C 05 B1 08 80 0B EE 0F FF 05 55 05 56 05 55
					39 00 00 40 00 00 02 6F 6F
					39 00 00 40 00 00 07 B0 02 1C 04 38 02 1C
					39 00 00 40 00 00 06 F0 55 AA 52 08 08
					39 00 00 40 00 00 17 C1 8D FF DD FF FF DD FF FF DD FF FF EE FF FF EE FF FF FE FF FF 0D FF
					39 00 00 40 00 00 02 6F 20
					39 00 00 40 00 00 04 C1 4F 00 FF
					39 00 00 40 00 00 02 6F 23
					39 00 00 40 00 00 15 C1 0D FF DD FF FF DD FF FF DD FF FF EE FF FF EE FF FF CE FF 51
					39 00 00 40 00 00 06 F0 55 AA 52 08 00
					39 00 00 40 00 00 02 C7 33
					39 00 00 40 00 00 02 6F 31
					39 00 00 40 00 00 03 C0 02 00
					39 00 00 40 00 00 06 F0 55 AA 52 08 04
					39 00 00 40 00 00 02 C0 20
					39 00 00 40 00 00 06 F0 55 AA 52 08 01
					39 00 00 40 00 00 03 B0 17 17
					39 00 00 40 00 00 06 B2 00 00 FF 03 20
					39 00 00 40 00 00 05 FF AA 55 A5 80
					39 00 00 40 00 00 02 6F 0A
					39 00 00 40 00 00 06 F6 70 70 70 70 70
					39 00 00 40 00 00 05 FF AA 55 A5 81
					39 00 00 40 00 00 02 6F 0C
					39 00 00 40 00 00 02 FD 08
					39 00 00 40 00 00 05 FF AA 55 A5 81
					39 00 00 40 00 00 02 6F 10
					39 00 00 40 00 00 02 FB 40
					39 00 00 40 00 00 05 FF AA 55 A5 81
					39 00 00 40 00 00 02 6F 13
					39 00 00 40 00 00 02 F9 00
					39 00 00 40 00 00 02 17 30
					39 00 00 40 00 00 05 2A 00 00 04 37
					39 00 00 40 00 00 05 2B 00 00 09 D7
					39 00 00 40 00 00 02 90 03
					39 00 00 40 00 00 02 6F 01
					39 00 00 40 00 00 02 90 43
					39 00 00 40 00 00 13 91 AB A8 00 14 C2 00 02 0E 01 E8 00 07 05 0E 05 16 10 F0
					39 00 00 40 00 00 02 6F 06
					39 00 00 40 00 00 02 6D 04
					39 00 00 40 00 00 02 2F 00
					39 00 00 40 00 00 03 5F 00 40
					39 00 00 40 00 00 02 35 00
					39 00 00 40 00 00 02 53 20
					39 00 00 40 00 00 02 26 00
					39 00 00 40 00 00 02 5A 00
					39 00 00 40 00 00 02 2F 30
					/* idle 120hz to 1hz */
					39 00 00 40 00 00 02 6D 09
					39 00 00 40 00 00 02 6F 04
					39 00 00 40 00 00 02 35 00
					39 00 00 40 00 00 06 F0 55 AA 52 08 00
					39 00 00 40 00 00 02 6F DE
					39 00 00 40 00 00 02 BA 00
					39 00 00 00 00 00 04 8C 02 00 11
					05 00 00 00 78 00 01 11
					05 00 00 00 00 00 01 29
				];
				qcom,mdss-dsi-on-command-state = "dsi_lp_mode";

				qcom,mdss-dsi-timing-switch-command = [
					39 00 00 40 00 00 02 6D 09
					39 00 00 40 00 00 02 6F 04
					39 00 00 40 00 00 02 35 00
					39 00 00 40 00 00 06 F0 55 AA 52 08 00
					39 00 00 40 00 00 02 6F DE
					39 00 00 40 00 00 02 BA 00
					39 00 00 00 00 00 04 8C 02 00 11
				];
				qcom,mdss-dsi-timing-switch-command-state = "dsi_lp_mode";

				qcom,mdss-dsi-nolp-command = [
					39 00 00 00 00 00 03 51 00 00
					/* AOD OFF */
					05 00 00 40 00 00 01 38
					39 00 00 40 00 00 02 5A 00
					39 00 00 40 00 00 02 6F 04
					39 00 00 00 00 00 02 35 00
				];
				qcom,mdss-dsi-nolp-command-update = <0x51 0 2>;
				qcom,mdss-dsi-nolp-command-state = "dsi_hs_mode";
			};
			timing@auto_120_to_1hz_index_8{
				#include "dsi-panel-o18-42-02-0a-sec-dsc-cmd-common.dtsi"
				cell-index = <8>;
				qcom,mdss-dsi-panel-framerate = <120>;
				/* ---------------------------- */
				/* | 15 - 14 | 13 - 7 | 6 - 0 | */
				/* ---------------------------- */
				/* |   mode  | sf fps | min fps| */
				/* ---------------------------- -*/
				/* mode: 1 idle, 2 auto, 3 qsync */
				/*   2 << 14 | 120 << 7 | 10     */
				qcom,mdss-dsi-h-sync-skew = <48129>;
				/* mode: 0 normal, 1 idle, 2 auto, 3 qsync, 4 diff, 5 test */
				mi,mdss-dsi-ddic-mode = "auto";
				mi,mdss-dsi-sf-framerate = <120>;
				mi,mdss-dsi-ddic-min-framerate = <1>;

				qcom,mdss-dsi-on-command = [
					39 00 00 40 00 00 06 F0 55 AA 52 08 00
					39 00 00 40 00 00 02 6F 78
					39 00 00 40 00 00 18 B0 11 00 2A 00 C2 01 DA 03 7C 05 B1 08 80 0B EE 0F FF 05 55 05 56 05 55
					39 00 00 40 00 00 02 6F 6F
					39 00 00 40 00 00 07 B0 02 1C 04 38 02 1C
					39 00 00 40 00 00 06 F0 55 AA 52 08 08
					39 00 00 40 00 00 17 C1 8D FF DD FF FF DD FF FF DD FF FF EE FF FF EE FF FF FE FF FF 0D FF
					39 00 00 40 00 00 02 6F 20
					39 00 00 40 00 00 04 C1 4F 00 FF
					39 00 00 40 00 00 02 6F 23
					39 00 00 40 00 00 15 C1 0D FF DD FF FF DD FF FF DD FF FF EE FF FF EE FF FF CE FF 51
					39 00 00 40 00 00 06 F0 55 AA 52 08 00
					39 00 00 40 00 00 02 C7 33
					39 00 00 40 00 00 02 6F 31
					39 00 00 40 00 00 03 C0 02 00
					39 00 00 40 00 00 06 F0 55 AA 52 08 04
					39 00 00 40 00 00 02 C0 20
					39 00 00 40 00 00 06 F0 55 AA 52 08 01
					39 00 00 40 00 00 03 B0 17 17
					39 00 00 40 00 00 06 B2 00 00 FF 03 20
					39 00 00 40 00 00 05 FF AA 55 A5 80
					39 00 00 40 00 00 02 6F 0A
					39 00 00 40 00 00 06 F6 70 70 70 70 70
					39 00 00 40 00 00 05 FF AA 55 A5 81
					39 00 00 40 00 00 02 6F 0C
					39 00 00 40 00 00 02 FD 08
					39 00 00 40 00 00 05 FF AA 55 A5 81
					39 00 00 40 00 00 02 6F 10
					39 00 00 40 00 00 02 FB 40
					39 00 00 40 00 00 05 FF AA 55 A5 81
					39 00 00 40 00 00 02 6F 13
					39 00 00 40 00 00 02 F9 00
					39 00 00 40 00 00 02 17 30
					39 00 00 40 00 00 05 2A 00 00 04 37
					39 00 00 40 00 00 05 2B 00 00 09 D7
					39 00 00 40 00 00 02 90 03
					39 00 00 40 00 00 02 6F 01
					39 00 00 40 00 00 02 90 43
					39 00 00 40 00 00 13 91 AB A8 00 14 C2 00 02 0E 01 E8 00 07 05 0E 05 16 10 F0
					39 00 00 40 00 00 02 6F 06
					39 00 00 40 00 00 02 6D 04
					39 00 00 40 00 00 02 2F 00
					39 00 00 40 00 00 03 5F 00 40
					39 00 00 40 00 00 02 35 00
					39 00 00 40 00 00 02 53 20
					39 00 00 40 00 00 02 26 00
					39 00 00 40 00 00 02 5A 00
					39 00 00 40 00 00 02 2F 30
					/* auto 120hz to 1hz */
					39 00 00 40 00 00 02 6D 09
					39 00 00 40 00 00 02 6F 04
					39 00 00 40 00 00 02 35 00
					39 00 00 40 00 00 06 F0 55 AA 52 08 00
					39 00 00 40 00 00 02 6F DE
					39 00 00 40 00 00 02 BA 00
					39 00 00 00 00 00 04 8C 02 00 11
					05 00 00 00 78 00 01 11
					05 00 00 00 00 00 01 29
				];
				qcom,mdss-dsi-on-command-state = "dsi_lp_mode";

				qcom,mdss-dsi-timing-switch-command = [
					39 00 00 40 00 00 02 6D 09
					39 00 00 40 00 00 02 6F 04
					39 00 00 40 00 00 02 35 00
					39 00 00 40 00 00 06 F0 55 AA 52 08 00
					39 00 00 40 00 00 02 6F DE
					39 00 00 40 00 00 02 BA 00
					39 00 00 00 00 00 04 8C 02 00 11
				];
				qcom,mdss-dsi-timing-switch-command-state = "dsi_lp_mode";

				qcom,mdss-dsi-nolp-command = [
					39 00 00 00 00 00 03 51 00 00
					/* AOD OFF */
					05 00 00 40 00 00 01 38
					39 00 00 40 00 00 02 5A 00
					39 00 00 40 00 00 02 6F 04
					39 00 00 00 00 00 02 35 00
				];
				qcom,mdss-dsi-nolp-command-update = <0x51 0 2>;
				qcom,mdss-dsi-nolp-command-state = "dsi_hs_mode";
			};
			timing@auto_60_to_10hz_index_9 {
				#include "dsi-panel-o18-42-02-0a-sec-dsc-cmd-common.dtsi"
				cell-index = <9>;
				qcom,mdss-dsi-panel-framerate = <60>;
				/* ---------------------------- */
				/* | 15 - 14 | 13 - 7 | 6 - 0 | */
				/* ---------------------------- */
				/* |   mode  | sf fps | min fps| */
				/* ---------------------------- -*/
				/* mode: 1 idle, 2 auto, 3 qsync */
				/*   2 << 14 | 60 << 7 | 10     */
				qcom,mdss-dsi-h-sync-skew = <40458>;
				/* mode: 0 normal, 1 idle, 2 auto, 3 qsync, 4 diff, 5 test */
				mi,mdss-dsi-ddic-mode = "auto";
				mi,mdss-dsi-sf-framerate = <60>;
				mi,mdss-dsi-ddic-min-framerate = <10>;

				qcom,mdss-dsi-on-command = [
					39 00 00 40 00 00 06 F0 55 AA 52 08 00
					39 00 00 40 00 00 02 6F 78
					39 00 00 40 00 00 18 B0 11 00 2A 00 C2 01 DA 03 7C 05 B1 08 80 0B EE 0F FF 05 55 05 56 05 55
					39 00 00 40 00 00 02 6F 6F
					39 00 00 40 00 00 07 B0 02 1C 04 38 02 1C
					39 00 00 40 00 00 06 F0 55 AA 52 08 08
					39 00 00 40 00 00 17 C1 8D FF DD FF FF DD FF FF DD FF FF EE FF FF EE FF FF FE FF FF 0D FF
					39 00 00 40 00 00 02 6F 20
					39 00 00 40 00 00 04 C1 4F 00 FF
					39 00 00 40 00 00 02 6F 23
					39 00 00 40 00 00 15 C1 0D FF DD FF FF DD FF FF DD FF FF EE FF FF EE FF FF CE FF 51
					39 00 00 40 00 00 06 F0 55 AA 52 08 00
					39 00 00 40 00 00 02 C7 33
					39 00 00 40 00 00 02 6F 31
					39 00 00 40 00 00 03 C0 02 00
					39 00 00 40 00 00 06 F0 55 AA 52 08 04
					39 00 00 40 00 00 02 C0 20
					39 00 00 40 00 00 06 F0 55 AA 52 08 01
					39 00 00 40 00 00 03 B0 17 17
					39 00 00 40 00 00 06 B2 00 00 FF 03 20
					39 00 00 40 00 00 05 FF AA 55 A5 80
					39 00 00 40 00 00 02 6F 0A
					39 00 00 40 00 00 06 F6 70 70 70 70 70
					39 00 00 40 00 00 05 FF AA 55 A5 81
					39 00 00 40 00 00 02 6F 0C
					39 00 00 40 00 00 02 FD 08
					39 00 00 40 00 00 05 FF AA 55 A5 81
					39 00 00 40 00 00 02 6F 10
					39 00 00 40 00 00 02 FB 40
					39 00 00 40 00 00 05 FF AA 55 A5 81
					39 00 00 40 00 00 02 6F 13
					39 00 00 40 00 00 02 F9 00
					39 00 00 40 00 00 02 17 30
					39 00 00 40 00 00 05 2A 00 00 04 37
					39 00 00 40 00 00 05 2B 00 00 09 D7
					39 00 00 40 00 00 02 90 03
					39 00 00 40 00 00 02 6F 01
					39 00 00 40 00 00 02 90 43
					39 00 00 40 00 00 13 91 AB A8 00 14 C2 00 02 0E 01 E8 00 07 05 0E 05 16 10 F0
					39 00 00 40 00 00 02 6F 06
					39 00 00 40 00 00 02 6D 04
					39 00 00 40 00 00 02 2F 00
					39 00 00 40 00 00 03 5F 00 40
					39 00 00 40 00 00 02 35 00
					39 00 00 40 00 00 02 53 20
					39 00 00 40 00 00 02 26 00
					39 00 00 40 00 00 02 5A 00
					39 00 00 40 00 00 02 2F 30
					/* auto 60hz to 10hz */
					39 00 00 40 00 00 02 6D 08
					39 00 00 40 00 00 02 6F 04
					39 00 00 40 00 00 02 35 01
					39 00 00 40 00 00 06 F0 55 AA 52 08 00
					39 00 00 40 00 00 02 6F DE
					39 00 00 40 00 00 02 BA 00
					39 00 00 00 00 00 04 8C 02 00 11
					05 00 00 00 78 00 01 11
					05 00 00 00 00 00 01 29
				];
				qcom,mdss-dsi-on-command-state = "dsi_lp_mode";

				qcom,mdss-dsi-timing-switch-command = [
					39 00 00 40 00 00 02 6D 08
					39 00 00 40 00 00 02 6F 04
					39 00 00 40 00 00 02 35 01
					39 00 00 40 00 00 06 F0 55 AA 52 08 00
					39 00 00 40 00 00 02 6F DE
					39 00 00 40 00 00 02 BA 00
					39 00 00 00 00 00 04 8C 02 00 11
				];
				qcom,mdss-dsi-timing-switch-command-state = "dsi_lp_mode";

				qcom,mdss-dsi-nolp-command = [
					39 00 00 00 00 00 03 51 00 00
					/* AOD OFF */
					05 00 00 40 00 00 01 38
					39 00 00 40 00 00 02 5A 00
					39 00 00 40 00 00 02 6F 04
					39 00 00 00 00 00 02 35 01
				];
				qcom,mdss-dsi-nolp-command-update = <0x51 0 2>;
				qcom,mdss-dsi-nolp-command-state = "dsi_hs_mode";
			};
		};
	};
};

&dsi_o18_42_02_0a_sec_dsc_cmd {
	qcom,panel-sec-supply-entries = <&dsi_panel_pwr_supply_sec_O18>;
	qcom,mdss-dsi-sec-bl-pmic-control-type = "bl_ctrl_dcs";
	qcom,mdss-dsi-bl-min-level = <25>;
	qcom,mdss-dsi-bl-max-level = <16383>;
	qcom,bl-dsc-cmd-state = "dsi_hs_mode";
	qcom,mdss-brightness-max-level = <16383>;
	qcom,mdss-brightness-init-level = <1228>;
	qcom,platform-sec-reset-gpio = <&tlmm 183 0>;

	mi,panel-build-id-read-needed;
	mi,panel-build-id-read-length = <1>;
	mi,mdss-dsi-panel-build-id-read-command = [06 01 00 01 00 00 01 DA];
	mi,mdss-dsi-panel-build-id-read-command-state = "dsi_hs_mode";

	mi,disable-ic-dimming-flag;
	qcom,mdss-dsi-panel-vsync-delay;
	qcom,ulps-enabled;
	qcom,dsi-select-sec-clocks = "pll_byte_clk1", "pll_dsi_clk1";
	qcom,mdss-dsi-clk-strength = <0xFF>;
	qcom,mdss-dsi-deemph-eq-strength = <0x88>;
};
